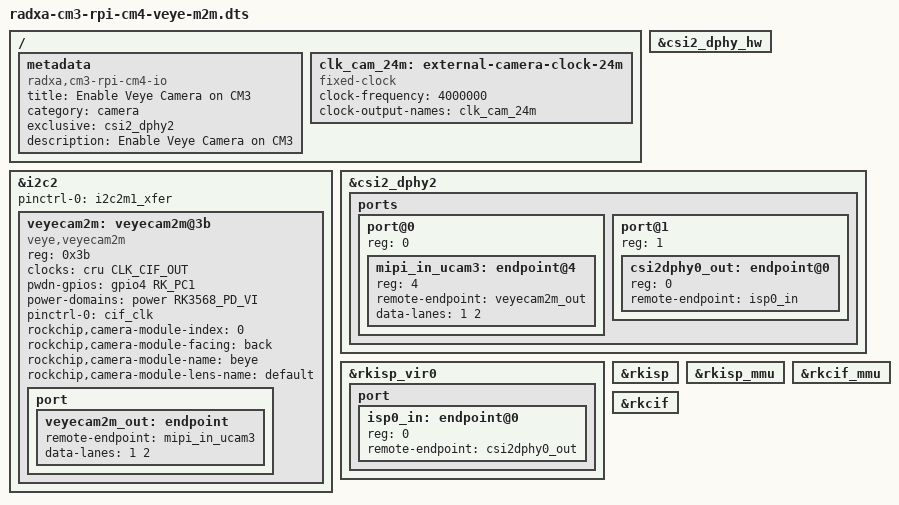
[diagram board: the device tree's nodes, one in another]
/dts-v1/;
/plugin/;

#include <dt-bindings/gpio/gpio.h>
#include <dt-bindings/pinctrl/rockchip.h>

/ {
	metadata {
		title = "Enable Veye Camera on CM3";
		compatible = "radxa,cm3-rpi-cm4-io";
		category = "camera";
		exclusive = "csi2_dphy2";
		description = "Enable Veye Camera on CM3";
	};

	fragment@0 {
		target-path = "/";

		__overlay__ {		
			clk_cam_24m: external-camera-clock-24m {
				status = "okay";
				compatible = "fixed-clock";
				clock-frequency = <4000000>;
				clock-output-names = "clk_cam_24m";
				#clock-cells = <0>;
			};
		};
	};

	fragment@1 {
		target = <&i2c2>;

		__overlay__ {
			status = "okay";
			pinctrl-names = "default";
			pinctrl-0 = <&i2c2m1_xfer>;
			#address-cells = <1>;
			#size-cells = <0>;

			veyecam2m: veyecam2m@3b {
				status = "okay";
				compatible = "veye,veyecam2m";
				reg = <0x3b>;
				clocks = <&cru CLK_CIF_OUT>;
				clock-names = "xvclk";
				pwdn-gpios = <&gpio4 RK_PC1 GPIO_ACTIVE_HIGH>;
				power-domains = <&power RK3568_PD_VI>;
				pinctrl-names = "default";
        		pinctrl-0 = <&cif_clk>;
				rockchip,camera-module-index = <0>;
				rockchip,camera-module-facing = "back";
				rockchip,camera-module-name = "beye";
				rockchip,camera-module-lens-name = "default";

				port {
					veyecam2m_out: endpoint {
						remote-endpoint = <&mipi_in_ucam3>;
						data-lanes = <1 2>;
					};
				};
			};
		};
	};

	fragment@2 {
		target = <&csi2_dphy_hw>;

		__overlay__ {
			status = "okay";
		};
	};

	fragment@3 {
		target = <&csi2_dphy2>;

		__overlay__ {
			status = "okay";

			ports {
				#address-cells = <1>;
				#size-cells = <0>;

				port@0 {
					reg = <0>;
					#address-cells = <1>;
					#size-cells = <0>;

					mipi_in_ucam3: endpoint@4 {
						reg = <4>;
						remote-endpoint = <&veyecam2m_out>;
						data-lanes = <1 2>;
					};
				};

				port@1 {
					reg = <1>;
					#address-cells = <1>;
					#size-cells = <0>;

					csi2dphy0_out: endpoint@0 {
						reg = <0>;
						remote-endpoint = <&isp0_in>;
					};
				};
			};
		};
	};

	fragment@4 {
		target = <&rkisp_vir0>;

		__overlay__ {
			status = "okay";

			port {
				#address-cells = <1>;
				#size-cells = <0>;

				isp0_in: endpoint@0 {
					reg = <0>;
					remote-endpoint = <&csi2dphy0_out>;
				};
			};
		};
	};

	fragment@5 {
		target = <&rkisp>;

		__overlay__ {
			status = "okay";
		};
	};

	fragment@6 {
		target = <&rkisp_mmu>;

		__overlay__ {
			status = "okay";
		};
	};

	fragment@7 {
		target = <&rkcif_mmu>;

		__overlay__ {
			status = "okay";
		};
	};

	fragment@8 {
		target = <&rkcif>;

		__overlay__ {
			status = "okay";
		};
	};

};
